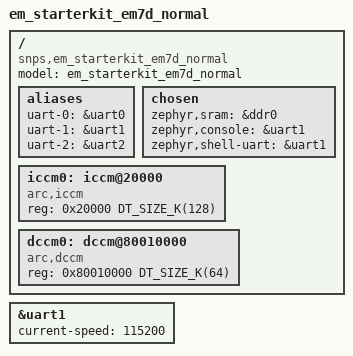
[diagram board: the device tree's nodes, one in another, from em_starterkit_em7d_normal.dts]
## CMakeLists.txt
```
# SPDX-License-Identifier: Apache-2.0

cmake_minimum_required(VERSION 3.28.0)

find_package(Zephyr REQUIRED HINTS $ENV{ZEPHYR_BASE})
project(arc_secure_services)

target_sources(app PRIVATE src/main.c)
```

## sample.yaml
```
sample:
  description: Sample application to verify the secure monitor for Designware ARC
    SecureShiled.
  name: Designware ARC Secure monitor
tests:
  sample.boards.arc_secure_services:
    # Requires multiple kernels in an AMP config. See README.rst
    build_only: true
    platform_allow:
      - nsim/nsim_sem
      - em_starterkit/emsk_em7d
    integration_platforms:
      - nsim/nsim_sem
    tags: secure
    harness: console
    harness_config:
      type: multi_line
      ordered: true
      regex:
        - "I am the main thread in secure world: 0"
        - "Go to normal application"
        - "I am the main thread in secure world: 1"
        - "I am the main thread in secure world: 2"
        - "I am the main thread in secure world: 3"
```

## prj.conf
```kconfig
CONFIG_SYS_TIMEOUT_LEGACY_API=y
```

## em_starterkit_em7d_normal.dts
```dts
/*
 * Copyright (c) 2018, Synopsys, Inc. All rights reserved.
 *
 * SPDX-License-Identifier: Apache-2.0
 */

/dts-v1/;

#include <mem.h>
#include <synopsys/emsk.dtsi>
#include "em_starterkit_r23.dtsi"
#include "board.dtsi"

/ {
	compatible = "snps,em_starterkit_em7d_normal", "snps,em_starterkit";
	model = "em_starterkit_em7d_normal";

	aliases {
		uart-0 = &uart0;
		uart-1 = &uart1;
		uart-2 = &uart2;
	};

	chosen {
		zephyr,sram = &ddr0;
		zephyr,console = &uart1;
		zephyr,shell-uart = &uart1;
	};

	iccm0: iccm@20000 {
		compatible = "arc,iccm";
		reg = <0x20000 DT_SIZE_K(128)>;
	};

	dccm0: dccm@80010000 {
		compatible = "arc,dccm";
		reg = <0x80010000 DT_SIZE_K(64)>;
	};
};

&uart1 {
	current-speed = <115200>;
	status = "okay";
};
```

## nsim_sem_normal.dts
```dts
/*
 * Copyright (c) 2018, Synopsys, Inc. All rights reserved.
 *
 * SPDX-License-Identifier: Apache-2.0
 */

/dts-v1/;

#include <mem.h>

/* must be before include of nsim_em.dtsi */
#define ICCM_ADDR 40000
#define ICCM_SIZE DT_SIZE_K(256)
#define DCCM_ADDR 80040000
#define DCCM_SIZE DT_SIZE_K(256)

#include "nsim_em.dtsi"

/ {
	compatible = "snps,nsim_sem_normal";
	model = "nsim_sem_normal";

	chosen {
		zephyr,sram = &dccm0;
	};
};
```

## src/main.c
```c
/*
 * Copyright (c) 2018 Synopsys.
 *
 * SPDX-License-Identifier: Apache-2.0
 */

#include <zephyr/kernel.h>
#include <zephyr/sys/printk.h>
#include <zephyr/devicetree.h>

#if defined(CONFIG_SOC_NSIM_SEM)
#define NORMAL_FIRMWARE_ENTRY 0x40000
#elif defined(CONFIG_SOC_EMSK)
#define NORMAL_FIRMWARE_ENTRY 0x20000
#endif


#define STACKSIZE 1024
#define PRIORITY 7
#define SLEEPTIME 1000


void threadA(void *dummy1, void *dummy2, void *dummy3)
{
	ARG_UNUSED(dummy1);
	ARG_UNUSED(dummy2);
	ARG_UNUSED(dummy3);


	printk("Go to normal application\n");

	arc_go_to_normal(*((uint32_t *)(NORMAL_FIRMWARE_ENTRY)));

	printk("should not come here\n");

}

K_THREAD_DEFINE(thread_a, STACKSIZE, threadA, NULL, NULL, NULL,
		PRIORITY, 0, 0);


int main(void)
{
	/* necessary configuration before go to normal */
	int32_t i = 0;

	/* allocate timer 0 and timer1 to normal mode */
	z_arc_v2_irq_uinit_secure_set(DT_IRQN(DT_NODELABEL(timer0)), 0);
	z_arc_v2_irq_uinit_secure_set(DT_IRQN(DT_NODELABEL(timer1)), 0);

	/* disable the secure interrupts for debug purpose*/
	/* _arc_v2_irq_unit_int_disable(IRQ_S_TIMER0); */

	while (1) {
		printk("I am the %s thread in secure world: %d\n",
				 __func__, i++);
		k_msleep(SLEEPTIME);
	}
	return 0;
}
```
